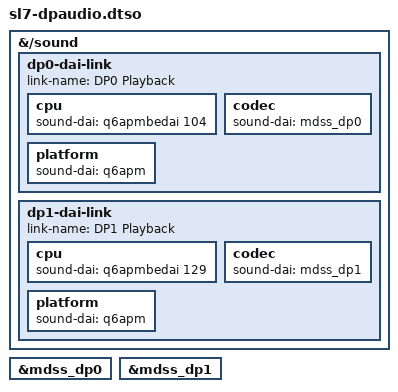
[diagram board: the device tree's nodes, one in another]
// Surface Laptop 7: audio over DisplayPort.
//
// The SoC devicetree describes the DP controllers and the machine driver
// (sound/soc/qcom/x1e80100.c) already handles DISPLAY_PORT_RX jacks, but the
// Romulus sound node declares no DP DAI links. Add them, plus the
// #sound-dai-cells the ASoC core needs to resolve the codec phandle.
//
// Template: arch/arm64/boot/dts/qcom/sc8280xp-lenovo-thinkpad-x13s.dts
// DAI ids: DISPLAY_PORT_RX_0 = 104, DISPLAY_PORT_RX_1 = 129
// (include/dt-bindings/sound/qcom,q6dsp-lpass-ports.h).
/dts-v1/;
/plugin/;

/ {
	fragment@0 {
		target-path = "/sound";
		__overlay__ {
			dp0-dai-link {
				link-name = "DP0 Playback";

				cpu {
					sound-dai = <&q6apmbedai 104>;
				};

				codec {
					sound-dai = <&mdss_dp0>;
				};

				platform {
					sound-dai = <&q6apm>;
				};
			};

			dp1-dai-link {
				link-name = "DP1 Playback";

				cpu {
					sound-dai = <&q6apmbedai 129>;
				};

				codec {
					sound-dai = <&mdss_dp1>;
				};

				platform {
					sound-dai = <&q6apm>;
				};
			};
		};
	};

	fragment@1 {
		target = <&mdss_dp0>;
		__overlay__ {
			#sound-dai-cells = <0>;
		};
	};

	fragment@2 {
		target = <&mdss_dp1>;
		__overlay__ {
			#sound-dai-cells = <0>;
		};
	};
};
